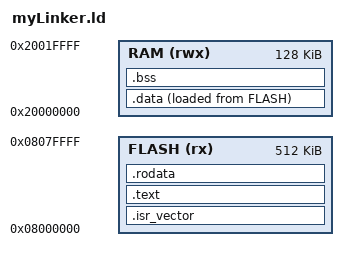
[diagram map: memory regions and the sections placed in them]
ENTRY(Reset_Handler)

_estack = ORIGIN(RAM) + LENGTH(RAM);

MEMORY
{
	FLASH (rx) : ORIGIN = 0x08000000, LENGTH = 512K
	RAM (rwx)  : ORIGIN = 0x20000000, LENGTH = 128K
}

SECTIONS
{
	.isr_vector :
	{
		. = ALIGN(4);
		KEEP(*(.isr_vector))
		. = ALIGN(4);
	} >FLASH

	.text :
	{
		. = ALIGN(4);
		*(.text)
		*(.text*)
		. = ALIGN(4);
	} >FLASH

	.rodata :
	{
		. = ALIGN(4);
		*(.rodata)
		*(.rodata*)
		. = ALIGN(4);
	} >FLASH

	.data :
	{
		. = ALIGN(4);
		_sdata = .;
		*(.data)
		*(.data*)

		. = ALIGN(4);
		_edata = .;
	} >RAM AT> FLASH

	_sidata = LOADADDR(.data);

	. = ALIGN(4);
	.bss :
	{
		_sbss = .;
		*(.bss)
		*(.bss*)

		. = ALIGN(4);
		_ebss = .;
	} >RAM
}
